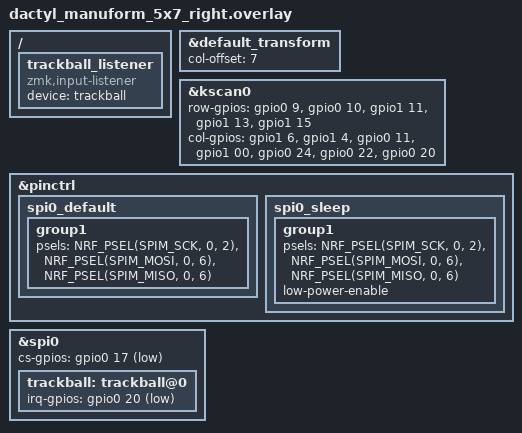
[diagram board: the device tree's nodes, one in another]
#include "dactyl_manuform_5x7.dtsi"
#include <zephyr/dt-bindings/input/input-event-codes.h>

&default_transform {
    col-offset = <7>;
};

&kscan0 {
    row-gpios
        = <&gpio0  9 (GPIO_ACTIVE_HIGH | GPIO_PULL_DOWN)>,
          <&gpio0  10 (GPIO_ACTIVE_HIGH | GPIO_PULL_DOWN)>,
          <&gpio1  11 (GPIO_ACTIVE_HIGH | GPIO_PULL_DOWN)>,
          <&gpio1  13 (GPIO_ACTIVE_HIGH | GPIO_PULL_DOWN)>,
          <&gpio1  15 (GPIO_ACTIVE_HIGH | GPIO_PULL_DOWN)>;

    col-gpios
        = <&gpio1 6 GPIO_ACTIVE_HIGH>,
          <&gpio1 4 GPIO_ACTIVE_HIGH>,
          <&gpio0 11 GPIO_ACTIVE_HIGH>,
          <&gpio1 00 GPIO_ACTIVE_HIGH>,
          <&gpio0 24 GPIO_ACTIVE_HIGH>,
          <&gpio0 22 GPIO_ACTIVE_HIGH>,
          <&gpio0 20 GPIO_ACTIVE_HIGH>;
};

&pinctrl {
  spi0_default: spi0_default {
    group1 {
      // SCK = P0.02, MOSI = P0.06, MISO = P0.06 (3-wire mode)
      psels = <NRF_PSEL(SPIM_SCK, 0, 2)>,
              <NRF_PSEL(SPIM_MOSI, 0, 6)>,
              <NRF_PSEL(SPIM_MISO, 0, 6)>;
    };
  };

  spi0_sleep: spi0_sleep {
    group1 {
      psels = <NRF_PSEL(SPIM_SCK, 0, 2)>,
              <NRF_PSEL(SPIM_MOSI, 0, 6)>,
              <NRF_PSEL(SPIM_MISO, 0, 6)>;
      low-power-enable;
    };
  };
};

&spi0 {
  status = "okay";
  cs-gpios = <&gpio0 17 GPIO_ACTIVE_LOW>; // nCS = P0.17

  trackball: trackball@0 {
    irq-gpios = <&gpio0 20 (GPIO_ACTIVE_LOW | GPIO_PULL_UP)>; // MOT = P0.20
  };
};

/ {
  trackball_listener {
    compatible = "zmk,input-listener";
    device = <&trackball>;
  };
};
